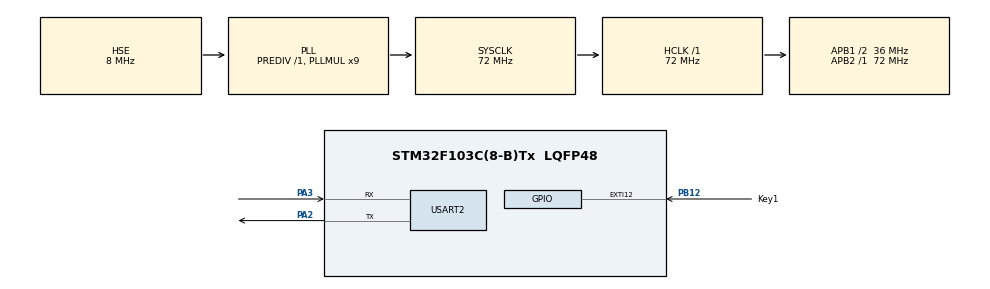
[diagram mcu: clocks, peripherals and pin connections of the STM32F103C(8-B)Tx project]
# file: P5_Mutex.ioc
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FREERTOS.BinarySemaphores01=SerialSem,Dynamic,NULL,Available;DangerSem,Dynamic,NULL,Depleted;TestSem,Dynamic,NULL,Depleted
FREERTOS.Mutexes01=SerialMutex,Dynamic,NULL,Available
FREERTOS.Tasks01=defaultTask,24,128,StartDefaultTask,Default,NULL,Dynamic,NULL,NULL;LogTask,8,128,StartLogTask,Default,NULL,Dynamic,NULL,NULL;AlarmTask,40,128,StartAlarmTask,Default,NULL,Dynamic,NULL,NULL
Mcu.Family=STM32F1
Mcu.Name=STM32F103C(8-B)Tx
Mcu.Package=LQFP48
NVIC.EXTI15_10_IRQn=true\:5\:0\:false\:false\:true\:true\:true\:true\:true
NVIC.PriorityGroup=NVIC_PRIORITYGROUP_4
NVIC.TIM4_IRQn=true\:15\:0\:false\:false\:true\:false\:false\:true\:true
NVIC.TimeBase=TIM4_IRQn
NVIC.TimeBaseIP=TIM4
PA13.Mode=Serial_Wire
PA13.Signal=SYS_JTMS-SWDIO
PA14.Mode=Serial_Wire
PA14.Signal=SYS_JTCK-SWCLK
PA2.Mode=Asynchronous
PA2.Signal=USART2_TX
PA3.Mode=Asynchronous
PA3.Signal=USART2_RX
PB12.GPIO_Label=Key1
PB12.GPIO_ModeDefaultEXTI=GPIO_MODE_IT_FALLING
PB12.GPIO_PuPd=GPIO_NOPULL
PB12.Signal=GPXTI12
PD0-OSC_IN.Mode=HSE-External-Oscillator
PD0-OSC_IN.Signal=RCC_OSC_IN
PD1-OSC_OUT.Mode=HSE-External-Oscillator
PD1-OSC_OUT.Signal=RCC_OSC_OUT
ProjectManager.HeapSize=0x200
ProjectManager.StackSize=0x400
ProjectManager.TargetToolchain=CMake
RCC.AHBFreq_Value=72000000
RCC.APB1CLKDivider=RCC_HCLK_DIV2
RCC.APB1Freq_Value=36000000
RCC.APB1TimFreq_Value=72000000
RCC.APB2Freq_Value=72000000
RCC.APB2TimFreq_Value=72000000
RCC.HCLKFreq_Value=72000000
RCC.PLLMUL=RCC_PLL_MUL9
RCC.PLLSourceVirtual=RCC_PLLSOURCE_HSE
RCC.SYSCLKFreq_VALUE=72000000
RCC.SYSCLKSource=RCC_SYSCLKSOURCE_PLLCLK
RCC.USBFreq_Value=72000000
USART2.VirtualMode=VM_ASYNC
VP_FREERTOS_VS_CMSIS_V2.Mode=CMSIS_V2
VP_SYS_VS_tim4.Mode=TIM4
board=custom

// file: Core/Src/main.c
/* USER CODE BEGIN Header */
/**
  ******************************************************************************
  * @file           : main.c
  * @brief          : Main program body
  ******************************************************************************
  * @attention
  *
  * Copyright (c) 2026 STMicroelectronics.
  * All rights reserved.
  *
  * This software is licensed under terms that can be found in the LICENSE file
  * in the root directory of this software component.
  * If no LICENSE file comes with this software, it is provided AS-IS.
  *
  ******************************************************************************
  */
/* USER CODE END Header */
#include "main.h"
#include "cmsis_os.h"

UART_HandleTypeDef huart2;

/* Definitions for defaultTask */
osThreadId_t defaultTaskHandle;
const osThreadAttr_t defaultTask_attributes = {
  .name = "defaultTask",
  .stack_size = 128 * 4,
  .priority = (osPriority_t) osPriorityNormal,
};
/* Definitions for LogTask */
osThreadId_t LogTaskHandle;
const osThreadAttr_t LogTask_attributes = {
  .name = "LogTask",
  .stack_size = 128 * 4,
  .priority = (osPriority_t) osPriorityLow,
};
/* Definitions for AlarmTask */
osThreadId_t AlarmTaskHandle;
const osThreadAttr_t AlarmTask_attributes = {
  .name = "AlarmTask",
  .stack_size = 128 * 4,
  .priority = (osPriority_t) osPriorityHigh,
};
/* Definitions for SerialMutex */
osMutexId_t SerialMutexHandle;
const osMutexAttr_t SerialMutex_attributes = {
  .name = "SerialMutex"
};
/* Definitions for SerialSem */
osSemaphoreId_t SerialSemHandle;
const osSemaphoreAttr_t SerialSem_attributes = {
  .name = "SerialSem"
};
/* Definitions for DangerSem */
osSemaphoreId_t DangerSemHandle;
const osSemaphoreAttr_t DangerSem_attributes = {
  .name = "DangerSem"
};
/* Definitions for TestSem */
osSemaphoreId_t TestSemHandle;
const osSemaphoreAttr_t TestSem_attributes = {
  .name = "TestSem"
};

void SystemClock_Config(void);
static void MX_GPIO_Init(void);
static void MX_USART2_UART_Init(void);
void StartDefaultTask(void *argument);
void StartLogTask(void *argument);
void StartAlarmTask(void *argument);

int main(void)
{

  /* MCU Configuration--------------------------------------------------------*/

  /* Reset of all peripherals, Initializes the Flash interface and the Systick. */
  HAL_Init();

  /* Configure the system clock */
  SystemClock_Config();

  /* Initialize all configured peripherals */
  MX_GPIO_Init();
  MX_USART2_UART_Init();

  /* Init scheduler */
  osKernelInitialize();
  /* Create the mutex(es) */
  /* creation of SerialMutex */
  SerialMutexHandle = osMutexNew(&SerialMutex_attributes);

  /* Create the semaphores(s) */
  /* creation of SerialSem */
  SerialSemHandle = osSemaphoreNew(1, 1, &SerialSem_attributes);

  /* creation of DangerSem */
  DangerSemHandle = osSemaphoreNew(1, 0, &DangerSem_attributes);

  /* creation of TestSem */
  TestSemHandle = osSemaphoreNew(1, 0, &TestSem_attributes);

  /* Create the thread(s) */
  /* creation of defaultTask */
  defaultTaskHandle = osThreadNew(StartDefaultTask, NULL, &defaultTask_attributes);

  /* creation of LogTask */
  LogTaskHandle = osThreadNew(StartLogTask, NULL, &LogTask_attributes);

  /* creation of AlarmTask */
  AlarmTaskHandle = osThreadNew(StartAlarmTask, NULL, &AlarmTask_attributes);

  /* Start scheduler */
  osKernelStart();

  /* We should never get here as control is now taken by the scheduler */

  /* Infinite loop */
  while (1)
  {

  }
}

void SystemClock_Config(void)
{
  RCC_OscInitTypeDef RCC_OscInitStruct = {0};
  RCC_ClkInitTypeDef RCC_ClkInitStruct = {0};

  /** Initializes the RCC Oscillators according to the specified parameters
  * in the RCC_OscInitTypeDef structure.
  */
  RCC_OscInitStruct.OscillatorType = RCC_OSCILLATORTYPE_HSE;
  RCC_OscInitStruct.HSEState = RCC_HSE_ON;
  RCC_OscInitStruct.HSEPredivValue = RCC_HSE_PREDIV_DIV1;
  RCC_OscInitStruct.HSIState = RCC_HSI_ON;
  RCC_OscInitStruct.PLL.PLLState = RCC_PLL_ON;
  RCC_OscInitStruct.PLL.PLLSource = RCC_PLLSOURCE_HSE;
  RCC_OscInitStruct.PLL.PLLMUL = RCC_PLL_MUL9;
  if (HAL_RCC_OscConfig(&RCC_OscInitStruct) != HAL_OK)
  {
    Error_Handler();
  }

  /** Initializes the CPU, AHB and APB buses clocks
  */
  RCC_ClkInitStruct.ClockType = RCC_CLOCKTYPE_HCLK|RCC_CLOCKTYPE_SYSCLK
                              |RCC_CLOCKTYPE_PCLK1|RCC_CLOCKTYPE_PCLK2;
  RCC_ClkInitStruct.SYSCLKSource = RCC_SYSCLKSOURCE_PLLCLK;
  RCC_ClkInitStruct.AHBCLKDivider = RCC_SYSCLK_DIV1;
  RCC_ClkInitStruct.APB1CLKDivider = RCC_HCLK_DIV2;
  RCC_ClkInitStruct.APB2CLKDivider = RCC_HCLK_DIV1;

  if (HAL_RCC_ClockConfig(&RCC_ClkInitStruct, FLASH_LATENCY_2) != HAL_OK)
  {
    Error_Handler();
  }
}

static void MX_USART2_UART_Init(void)
{

  huart2.Instance = USART2;
  huart2.Init.BaudRate = 115200;
  huart2.Init.WordLength = UART_WORDLENGTH_8B;
  huart2.Init.StopBits = UART_STOPBITS_1;
  huart2.Init.Parity = UART_PARITY_NONE;
  huart2.Init.Mode = UART_MODE_TX_RX;
  huart2.Init.HwFlowCtl = UART_HWCONTROL_NONE;
  huart2.Init.OverSampling = UART_OVERSAMPLING_16;
  if (HAL_UART_Init(&huart2) != HAL_OK)
  {
    Error_Handler();
  }

}

static void MX_GPIO_Init(void)
{
  GPIO_InitTypeDef GPIO_InitStruct = {0};

  /* GPIO Ports Clock Enable */
  __HAL_RCC_GPIOD_CLK_ENABLE();
  __HAL_RCC_GPIOA_CLK_ENABLE();
  __HAL_RCC_GPIOB_CLK_ENABLE();

  /*Configure GPIO pin : Key1_Pin */
  GPIO_InitStruct.Pin = Key1_Pin;
  GPIO_InitStruct.Mode = GPIO_MODE_IT_FALLING;
  GPIO_InitStruct.Pull = GPIO_NOPULL;
  HAL_GPIO_Init(Key1_GPIO_Port, &GPIO_InitStruct);

  /* EXTI interrupt init*/
  HAL_NVIC_SetPriority(EXTI15_10_IRQn, 5, 0);
  HAL_NVIC_EnableIRQ(EXTI15_10_IRQn);

}

void StartDefaultTask(void *argument)
{
  for(;;)
  {
    osDelay(1);
  }
}

void StartLogTask(void *argument)
{
  for(;;)
  {
    osDelay(1);
  }
}

void StartAlarmTask(void *argument)
{
  for(;;)
  {
    osDelay(1);
  }
}

void HAL_TIM_PeriodElapsedCallback(TIM_HandleTypeDef *htim)
{
  if (htim->Instance == TIM4)
  {
    HAL_IncTick();
  }
}

void Error_Handler(void)
{
  __disable_irq();
  while (1)
  {
  }
}

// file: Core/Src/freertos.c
/* USER CODE BEGIN Header */
/**
  ******************************************************************************
  * File Name          : freertos.c
  * Description        : Code for freertos applications
  ******************************************************************************
  * @attention
  *
  * Copyright (c) 2026 STMicroelectronics.
  * All rights reserved.
  *
  * This software is licensed under terms that can be found in the LICENSE file
  * in the root directory of this software component.
  * If no LICENSE file comes with this software, it is provided AS-IS.
  *
  ******************************************************************************
  */
/* USER CODE END Header */

#include "FreeRTOS.h"
#include "task.h"
#include "main.h"
#include "cmsis_os.h"

/* USER CODE BEGIN Includes */
#include <stdio.h>
#include <string.h>
#include "usart.h"
/* USER CODE END Includes */

/* Definitions for defaultTask */
osThreadId_t defaultTaskHandle;
const osThreadAttr_t defaultTask_attributes = {
  .name = "defaultTask",
  .stack_size = 128 * 4,
  .priority = (osPriority_t) osPriorityNormal,
};
/* Definitions for LogTask */
osThreadId_t LogTaskHandle;
const osThreadAttr_t LogTask_attributes = {
  .name = "LogTask",
  .stack_size = 128 * 4,
  .priority = (osPriority_t) osPriorityLow,
};
/* Definitions for AlarmTask */
osThreadId_t AlarmTaskHandle;
const osThreadAttr_t AlarmTask_attributes = {
  .name = "AlarmTask",
  .stack_size = 128 * 4,
  .priority = (osPriority_t) osPriorityHigh,
};
/* Definitions for SerialMutex */
osMutexId_t SerialMutexHandle;
const osMutexAttr_t SerialMutex_attributes = {
  .name = "SerialMutex"
};
/* Definitions for SerialSem */
osSemaphoreId_t SerialSemHandle;
const osSemaphoreAttr_t SerialSem_attributes = {
  .name = "SerialSem"
};
/* Definitions for DangerSem */
osSemaphoreId_t DangerSemHandle;
const osSemaphoreAttr_t DangerSem_attributes = {
  .name = "DangerSem"
};
/* Definitions for TestSem */
osSemaphoreId_t TestSemHandle;
const osSemaphoreAttr_t TestSem_attributes = {
  .name = "TestSem"
};

void StartDefaultTask(void *argument);
void StartLogTask(void *argument);
void StartAlarmTask(void *argument);

void MX_FREERTOS_Init(void); /* (MISRA C 2004 rule 8.1) */

void MX_FREERTOS_Init(void) {
  /* Create the mutex(es) */
  /* creation of SerialMutex */
  SerialMutexHandle = osMutexNew(&SerialMutex_attributes);

  /* Create the semaphores(s) */
  /* creation of SerialSem */
  SerialSemHandle = osSemaphoreNew(1, 1, &SerialSem_attributes);

  /* creation of DangerSem */
  DangerSemHandle = osSemaphoreNew(1, 0, &DangerSem_attributes);

  /* creation of TestSem */
  TestSemHandle = osSemaphoreNew(1, 0, &TestSem_attributes);

  /* Create the thread(s) */
  /* creation of defaultTask */
  defaultTaskHandle = osThreadNew(StartDefaultTask, NULL, &defaultTask_attributes);

  /* creation of LogTask */
  LogTaskHandle = osThreadNew(StartLogTask, NULL, &LogTask_attributes);

  /* creation of AlarmTask */
  AlarmTaskHandle = osThreadNew(StartAlarmTask, NULL, &AlarmTask_attributes);

}

void StartDefaultTask(void *argument)
{
  /* USER CODE BEGIN StartDefaultTask */
  /* Infinite loop */
  for(;;)
  {
    osSemaphoreAcquire(TestSemHandle, osWaitForever);   /* 平时阻塞，按键后唤醒 */
    HAL_Delay(3000);                                      /* 忙等 3 秒，抢占 CPU */
  }
  /* USER CODE END StartDefaultTask */
}

void StartLogTask(void *argument)
{
  /* USER CODE BEGIN StartLogTask */
  int counter = 0;
  char msg[30];
  /* Infinite loop */
  for(;;)
  {
    osSemaphoreAcquire(SerialSemHandle, osWaitForever);
    // osMutexAcquire(SerialMutexHandle, osWaitForever);

    counter++;
    sprintf(msg, "日志：%d", counter);
    HAL_UART_Transmit(&huart2, (uint8_t *)msg, strlen(msg), HAL_MAX_DELAY);
    osDelay(500);
    osSemaphoreRelease(SerialSemHandle);
    // osMutexRelease(SerialMutexHandle);
  }
  /* USER CODE END StartLogTask */
}

void StartAlarmTask(void *argument)
{
  /* USER CODE BEGIN StartAlarmTask */
  char msg[] = "🚨 警报 警报";
  /* Infinite loop */
  for(;;)
  {
    osSemaphoreAcquire(DangerSemHandle, osWaitForever);

    osSemaphoreAcquire(SerialSemHandle, osWaitForever);
    // osMutexAcquire(SerialMutexHandle, osWaitForever);

    HAL_UART_Transmit(&huart2, (uint8_t *)msg, strlen(msg), HAL_MAX_DELAY);

    osSemaphoreRelease(SerialSemHandle);
    // osMutexRelease(SerialMutexHandle);
  }
  /* USER CODE END StartAlarmTask */
}
